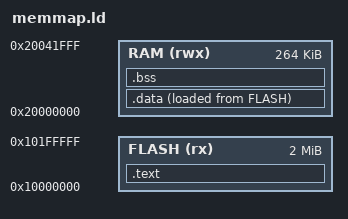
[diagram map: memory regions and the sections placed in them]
MEMORY
{
    FLASH(rx) : ORIGIN = 0x10000000, LENGTH = 2048k
    RAM(rwx) : ORIGIN = 0x20000000, LENGTH = 264k
}

ENTRY(Reset_Handler)

SECTIONS
{
    .text :
    {
        KEEP(*(.vectors))
        *(.text*)
        *(.rodata*)
    } > FLASH

    .data :
    {
        __data_start__ = .;
        *(.data*)
        __data_end__ = .;
    } > RAM AT > FLASH

    .bss :
    {
        __bss_start__ = .;
        *(.bss*)
        *(COMMON)
        __bss_end__ = .;
    } > RAM

    __stack_top = ORIGIN(RAM) + LENGTH(RAM);
}
